VERSION ""

NS_ :

BS_:

BU_:

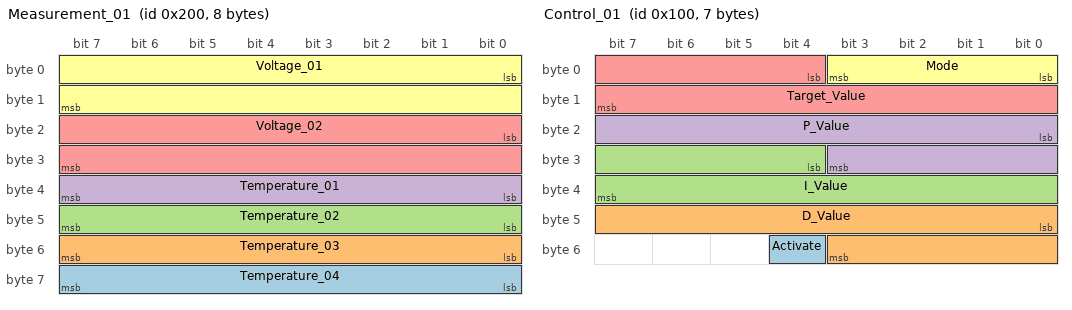
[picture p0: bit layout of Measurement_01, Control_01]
BO_ 512 Measurement_01: 8 Vector__XXX
 SG_ Temperature_04 : 56|8@1+ (0.5,-40) [-40|87.5] "" Vector__XXX
 SG_ Temperature_03 : 48|8@1+ (0.5,-40) [-40|87.5] "" Vector__XXX
 SG_ Temperature_02 : 40|8@1+ (0.5,-40) [-40|87.5] "" Vector__XXX
 SG_ Temperature_01 : 32|8@1+ (0.5,-40) [-40|87.5] "" Vector__XXX
 SG_ Voltage_02 : 16|16@1+ (0.01,0) [0|655.35] "" Vector__XXX
 SG_ Voltage_01 : 0|16@1+ (0.01,0) [0|655.35] "" Vector__XXX

BO_ 256 Control_01: 7 Vector__XXX
 SG_ Activate : 52|1@1+ (1,0) [0|0] "" Vector__XXX
 SG_ D_Value : 40|12@1+ (0.01,0) [0|40.95] "" Vector__XXX
 SG_ I_Value : 28|12@1+ (0.01,0) [0|40.95] "" Vector__XXX
 SG_ P_Value : 16|12@1+ (0.01,0) [0|40.95] "" Vector__XXX
 SG_ Target_Value : 4|12@1+ (1,0) [0|4095] "rpm" Vector__XXX
 SG_ Mode : 0|4@1+ (1,0) [0|15] "" Vector__XXX
